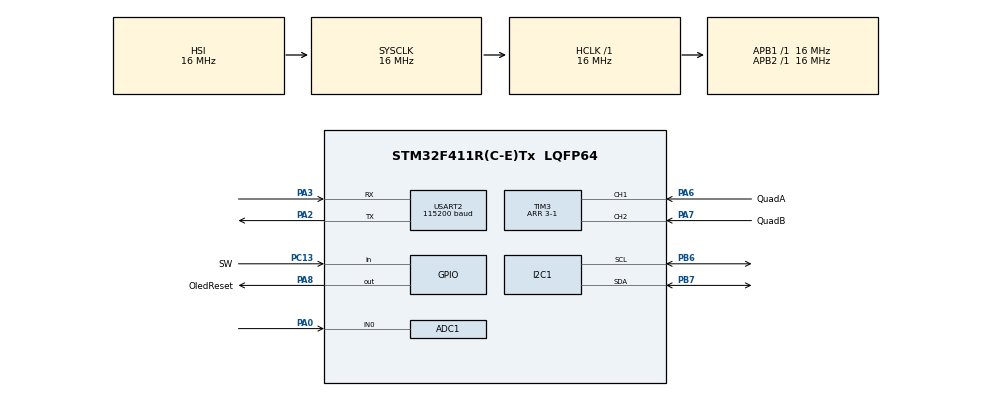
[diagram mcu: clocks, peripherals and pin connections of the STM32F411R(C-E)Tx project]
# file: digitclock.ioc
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ADC1.Channel-0\#ChannelRegularConversion=ADC_CHANNEL_0
ADC1.ClockPrescaler=ADC_CLOCK_SYNC_PCLK_DIV4
ADC1.NbrOfConversionFlag=1
ADC1.Rank-0\#ChannelRegularConversion=1
ADC1.SamplingTime-0\#ChannelRegularConversion=ADC_SAMPLETIME_3CYCLES
ADC1.master=1
I2C1.I2C_Mode=I2C_Fast
Mcu.Family=STM32F4
Mcu.Name=STM32F411R(C-E)Tx
Mcu.Package=LQFP64
NVIC.PriorityGroup=NVIC_PRIORITYGROUP_4
NVIC.USART2_IRQn=true\:0\:0\:false\:false\:true\:true\:true\:true
PA0-WKUP.Signal=ADCx_IN0
PA2.Mode=Asynchronous
PA2.Signal=USART2_TX
PA3.Mode=Asynchronous
PA3.Signal=USART2_RX
PA6.GPIO_Label=QuadA
PA6.Signal=S_TIM3_CH1
PA7.GPIO_Label=QuadB
PA7.Signal=S_TIM3_CH2
PA8.GPIO_Label=OledReset
PA8.Signal=GPIO_Output
PB6.GPIO_Pu=GPIO_PULLUP
PB6.Mode=I2C
PB6.Signal=I2C1_SCL
PB7.GPIO_Pu=GPIO_PULLUP
PB7.Mode=I2C
PB7.Signal=I2C1_SDA
PC13-ANTI_TAMP.GPIO_Label=SW
PC13-ANTI_TAMP.Signal=GPIO_Input
ProjectManager.HeapSize=0x200
ProjectManager.StackSize=0x400
ProjectManager.TargetToolchain=STM32CubeIDE
RCC.AHBFreq_Value=16000000
RCC.APB1Freq_Value=16000000
RCC.APB2Freq_Value=16000000
RCC.CortexFreq_Value=16000000
RCC.HSE_VALUE=25000000
RCC.HSI_VALUE=16000000
RCC.LSE_VALUE=32768
RCC.SYSCLKFreq_VALUE=16000000
RCC.VCOOutputFreq_Value=192000000
SH.ADCx_IN0.0=ADC1_IN0,IN0
SH.S_TIM3_CH1.0=TIM3_CH1,Encoder_Interface
SH.S_TIM3_CH2.0=TIM3_CH2,Encoder_Interface
TIM3.Period=3-1
USART2.BaudRate=115200
USART2.VirtualMode=VM_ASYNC
board=custom

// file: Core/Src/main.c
/* USER CODE BEGIN Header */
/**
  ******************************************************************************
  * @file           : main.c
  * @brief          : Main program body
  ******************************************************************************
  * @attention
  *
  * Copyright (c) 2024 STMicroelectronics.
  * All rights reserved.
  *
  * This software is licensed under terms that can be found in the LICENSE file
  * in the root directory of this software component.
  * If no LICENSE file comes with this software, it is provided AS-IS.
  *
  ******************************************************************************
  */
/* USER CODE END Header */
#include "main.h"

ADC_HandleTypeDef hadc1;

I2C_HandleTypeDef hi2c1;

TIM_HandleTypeDef htim3;

UART_HandleTypeDef huart2;

void SystemClock_Config(void);
static void MX_GPIO_Init(void);
static void MX_I2C1_Init(void);
static void MX_TIM3_Init(void);
static void MX_USART2_UART_Init(void);
static void MX_ADC1_Init(void);

int main(void)
{

  /* MCU Configuration--------------------------------------------------------*/

  /* Reset of all peripherals, Initializes the Flash interface and the Systick. */
  HAL_Init();

  /* Configure the system clock */
  SystemClock_Config();

  /* Initialize all configured peripherals */
  MX_GPIO_Init();
  MX_I2C1_Init();
  MX_TIM3_Init();
  MX_USART2_UART_Init();
  MX_ADC1_Init();
  /* USER CODE BEGIN 2 */
  app();
  //Uart();
  /* USER CODE END 2 */

  /* Infinite loop */
  while (1)
  {

  }
}

void SystemClock_Config(void)
{
  RCC_OscInitTypeDef RCC_OscInitStruct = {0};
  RCC_ClkInitTypeDef RCC_ClkInitStruct = {0};

  /** Configure the main internal regulator output voltage
  */
  __HAL_RCC_PWR_CLK_ENABLE();
  __HAL_PWR_VOLTAGESCALING_CONFIG(PWR_REGULATOR_VOLTAGE_SCALE1);

  /** Initializes the RCC Oscillators according to the specified parameters
  * in the RCC_OscInitTypeDef structure.
  */
  RCC_OscInitStruct.OscillatorType = RCC_OSCILLATORTYPE_HSI;
  RCC_OscInitStruct.HSIState = RCC_HSI_ON;
  RCC_OscInitStruct.HSICalibrationValue = RCC_HSICALIBRATION_DEFAULT;
  RCC_OscInitStruct.PLL.PLLState = RCC_PLL_NONE;
  if (HAL_RCC_OscConfig(&RCC_OscInitStruct) != HAL_OK)
  {
    Error_Handler();
  }

  /** Initializes the CPU, AHB and APB buses clocks
  */
  RCC_ClkInitStruct.ClockType = RCC_CLOCKTYPE_HCLK|RCC_CLOCKTYPE_SYSCLK
                              |RCC_CLOCKTYPE_PCLK1|RCC_CLOCKTYPE_PCLK2;
  RCC_ClkInitStruct.SYSCLKSource = RCC_SYSCLKSOURCE_HSI;
  RCC_ClkInitStruct.AHBCLKDivider = RCC_SYSCLK_DIV1;
  RCC_ClkInitStruct.APB1CLKDivider = RCC_HCLK_DIV1;
  RCC_ClkInitStruct.APB2CLKDivider = RCC_HCLK_DIV1;

  if (HAL_RCC_ClockConfig(&RCC_ClkInitStruct, FLASH_LATENCY_0) != HAL_OK)
  {
    Error_Handler();
  }
}

static void MX_ADC1_Init(void)
{

  ADC_ChannelConfTypeDef sConfig = {0};

  /** Configure the global features of the ADC (Clock, Resolution, Data Alignment and number of conversion)
  */
  hadc1.Instance = ADC1;
  hadc1.Init.ClockPrescaler = ADC_CLOCK_SYNC_PCLK_DIV4;
  hadc1.Init.Resolution = ADC_RESOLUTION_12B;
  hadc1.Init.ScanConvMode = DISABLE;
  hadc1.Init.ContinuousConvMode = DISABLE;
  hadc1.Init.DiscontinuousConvMode = DISABLE;
  hadc1.Init.ExternalTrigConvEdge = ADC_EXTERNALTRIGCONVEDGE_NONE;
  hadc1.Init.ExternalTrigConv = ADC_SOFTWARE_START;
  hadc1.Init.DataAlign = ADC_DATAALIGN_RIGHT;
  hadc1.Init.NbrOfConversion = 1;
  hadc1.Init.DMAContinuousRequests = DISABLE;
  hadc1.Init.EOCSelection = ADC_EOC_SINGLE_CONV;
  if (HAL_ADC_Init(&hadc1) != HAL_OK)
  {
    Error_Handler();
  }

  /** Configure for the selected ADC regular channel its corresponding rank in the sequencer and its sample time.
  */
  sConfig.Channel = ADC_CHANNEL_0;
  sConfig.Rank = 1;
  sConfig.SamplingTime = ADC_SAMPLETIME_3CYCLES;
  if (HAL_ADC_ConfigChannel(&hadc1, &sConfig) != HAL_OK)
  {
    Error_Handler();
  }

}

static void MX_I2C1_Init(void)
{

  hi2c1.Instance = I2C1;
  hi2c1.Init.ClockSpeed = 400000;
  hi2c1.Init.DutyCycle = I2C_DUTYCYCLE_2;
  hi2c1.Init.OwnAddress1 = 0;
  hi2c1.Init.AddressingMode = I2C_ADDRESSINGMODE_7BIT;
  hi2c1.Init.DualAddressMode = I2C_DUALADDRESS_DISABLE;
  hi2c1.Init.OwnAddress2 = 0;
  hi2c1.Init.GeneralCallMode = I2C_GENERALCALL_DISABLE;
  hi2c1.Init.NoStretchMode = I2C_NOSTRETCH_DISABLE;
  if (HAL_I2C_Init(&hi2c1) != HAL_OK)
  {
    Error_Handler();
  }

}

static void MX_TIM3_Init(void)
{

  TIM_Encoder_InitTypeDef sConfig = {0};
  TIM_MasterConfigTypeDef sMasterConfig = {0};

  htim3.Instance = TIM3;
  htim3.Init.Prescaler = 0;
  htim3.Init.CounterMode = TIM_COUNTERMODE_UP;
  htim3.Init.Period = 3-1;
  htim3.Init.ClockDivision = TIM_CLOCKDIVISION_DIV1;
  htim3.Init.AutoReloadPreload = TIM_AUTORELOAD_PRELOAD_DISABLE;
  sConfig.EncoderMode = TIM_ENCODERMODE_TI1;
  sConfig.IC1Polarity = TIM_ICPOLARITY_RISING;
  sConfig.IC1Selection = TIM_ICSELECTION_DIRECTTI;
  sConfig.IC1Prescaler = TIM_ICPSC_DIV1;
  sConfig.IC1Filter = 0;
  sConfig.IC2Polarity = TIM_ICPOLARITY_RISING;
  sConfig.IC2Selection = TIM_ICSELECTION_DIRECTTI;
  sConfig.IC2Prescaler = TIM_ICPSC_DIV1;
  sConfig.IC2Filter = 0;
  if (HAL_TIM_Encoder_Init(&htim3, &sConfig) != HAL_OK)
  {
    Error_Handler();
  }
  sMasterConfig.MasterOutputTrigger = TIM_TRGO_RESET;
  sMasterConfig.MasterSlaveMode = TIM_MASTERSLAVEMODE_DISABLE;
  if (HAL_TIMEx_MasterConfigSynchronization(&htim3, &sMasterConfig) != HAL_OK)
  {
    Error_Handler();
  }

}

static void MX_USART2_UART_Init(void)
{

  huart2.Instance = USART2;
  huart2.Init.BaudRate = 115200;
  huart2.Init.WordLength = UART_WORDLENGTH_8B;
  huart2.Init.StopBits = UART_STOPBITS_1;
  huart2.Init.Parity = UART_PARITY_NONE;
  huart2.Init.Mode = UART_MODE_TX_RX;
  huart2.Init.HwFlowCtl = UART_HWCONTROL_NONE;
  huart2.Init.OverSampling = UART_OVERSAMPLING_16;
  if (HAL_UART_Init(&huart2) != HAL_OK)
  {
    Error_Handler();
  }

}

static void MX_GPIO_Init(void)
{
  GPIO_InitTypeDef GPIO_InitStruct = {0};

  /* GPIO Ports Clock Enable */
  __HAL_RCC_GPIOC_CLK_ENABLE();
  __HAL_RCC_GPIOA_CLK_ENABLE();
  __HAL_RCC_GPIOB_CLK_ENABLE();

  /*Configure GPIO pin Output Level */
  HAL_GPIO_WritePin(OledReset_GPIO_Port, OledReset_Pin, GPIO_PIN_RESET);

  /*Configure GPIO pin : SW_Pin */
  GPIO_InitStruct.Pin = SW_Pin;
  GPIO_InitStruct.Mode = GPIO_MODE_INPUT;
  GPIO_InitStruct.Pull = GPIO_NOPULL;
  HAL_GPIO_Init(SW_GPIO_Port, &GPIO_InitStruct);

  /*Configure GPIO pin : OledReset_Pin */
  GPIO_InitStruct.Pin = OledReset_Pin;
  GPIO_InitStruct.Mode = GPIO_MODE_OUTPUT_PP;
  GPIO_InitStruct.Pull = GPIO_NOPULL;
  GPIO_InitStruct.Speed = GPIO_SPEED_FREQ_LOW;
  HAL_GPIO_Init(OledReset_GPIO_Port, &GPIO_InitStruct);

}

void Error_Handler(void)
{
  __disable_irq();
  while (1)
  {
  }
}
